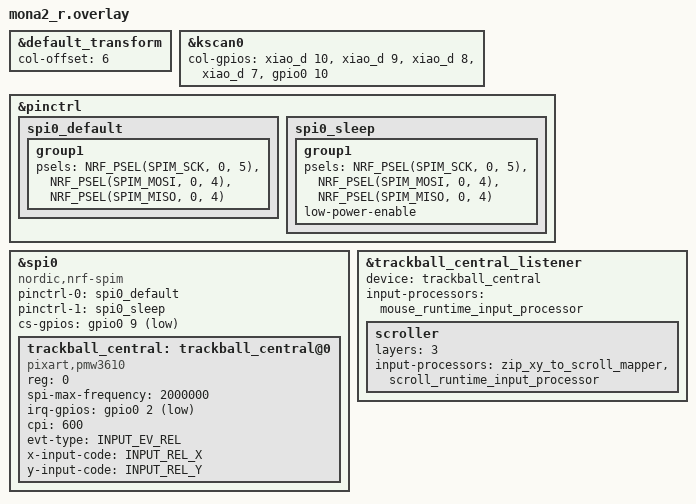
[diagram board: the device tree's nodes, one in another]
#include "mona2.dtsi"
#include <input/processors.dtsi>
#include <input/processors/runtime-input-processor.dtsi>
#include <zephyr/dt-bindings/input/input-event-codes.h>


&default_transform {
    col-offset = <6>;
};

&kscan0 {
        col-gpios
            = <&xiao_d 10 GPIO_ACTIVE_HIGH>
            , <&xiao_d 9 GPIO_ACTIVE_HIGH> 
            , <&xiao_d 8 GPIO_ACTIVE_HIGH> 
            , <&xiao_d 7 GPIO_ACTIVE_HIGH> 
            , <&gpio0 10 GPIO_ACTIVE_HIGH>
            ;
};


&pinctrl {
    spi0_default: spi0_default {    //騾壼ｸｸ譎・SPI騾壻ｿ｡荳ｭ)縺ｮ繝斐Φ讒区・
        group1 {
            psels = <NRF_PSEL(SPIM_SCK, 0, 5)>, //P0.05繧呈欠螳・SCLK)
                <NRF_PSEL(SPIM_MOSI, 0, 4)>,    //P0.04繧呈欠螳・SDIO縺縺九ｉMOSI,MISO荳｡譁ｹ縺ｮ蠖ｹ蜑ｲ繧呈球縺・
                <NRF_PSEL(SPIM_MISO, 0, 4)>;
        };
    };

    spi0_sleep: spi0_sleep {    //繧ｹ繝ｪ繝ｼ繝玲凾縺ｮ繝斐Φ讒区・(逵・崕蜉・
        group1 {
            psels = <NRF_PSEL(SPIM_SCK, 0, 5)>,
                <NRF_PSEL(SPIM_MOSI, 0, 4)>,
                <NRF_PSEL(SPIM_MISO, 0, 4)>;
            low-power-enable;
        };
    };
};


&spi0 {
    status = "okay";
    compatible = "nordic,nrf-spim"; //繝槭う繧ｳ繝ｳ縺系RF繧ｷ繝ｪ繝ｼ繧ｺ
    pinctrl-0 = <&spi0_default>;
    pinctrl-1 = <&spi0_sleep>;
    pinctrl-names = "default", "sleep";
    cs-gpios = <&gpio0 9 GPIO_ACTIVE_LOW>;  //P0.09繧呈欠螳・CS)

    trackball_central: trackball_central@0 {
        status = "okay";
        compatible = "pixart,pmw3610";  //繝医Λ繝懊そ繝ｳ繧ｵ逕ｨ縺ｮ繝峨Λ繧､繝舌→繝舌う繝ｳ繝・
        reg = <0>;
        spi-max-frequency = <2000000>;
        irq-gpios = <&gpio0 2 (GPIO_ACTIVE_LOW | GPIO_PULL_UP)>; //P0.02繧呈欠螳・MOTION)
        cpi = <600>;
        //swap-xy;
        //invert-x; //COROPIT迚医〒縺ｯ繧ｳ繝｡繝ｳ繝医い繧ｦ繝医ｒ螟悶☆
        //invert-y; //COROPIT迚医〒縺ｯ繧ｳ繝｡繝ｳ繝医い繧ｦ繝医ｒ螟悶☆
        evt-type = <INPUT_EV_REL>;
        x-input-code = <INPUT_REL_X>;
        y-input-code = <INPUT_REL_Y>;
    };
};


// Overrides for the input listener node
&trackball_central_listener {
    status = "okay";
    device = <&trackball_central>;
    input-processors = <&mouse_runtime_input_processor>;

    scroller {
        layers = <3>;
        input-processors = <&zip_xy_to_scroll_mapper &scroll_runtime_input_processor>;
    };
};
